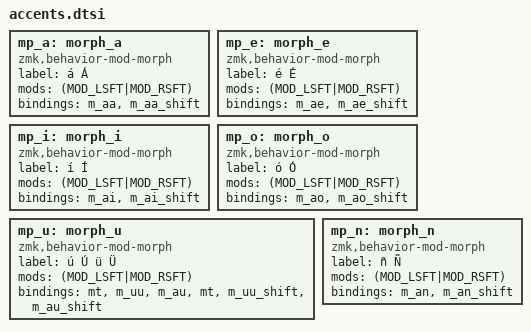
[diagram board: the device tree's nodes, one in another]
mp_a: morph_a {
    compatible = "zmk,behavior-mod-morph";
    label = "á Á";
    #binding-cells = <0>;
    mods = <(MOD_LSFT|MOD_RSFT)>;
    bindings = <&m_aa>, <&m_aa_shift>;
};

mp_e: morph_e {
    compatible = "zmk,behavior-mod-morph";
    label = "é É";
    #binding-cells = <0>;
    mods = <(MOD_LSFT|MOD_RSFT)>;
    bindings = <&m_ae>, <&m_ae_shift>;
};

mp_i: morph_i {
    compatible = "zmk,behavior-mod-morph";
    label = "í Í";
    #binding-cells = <0>;
    mods = <(MOD_LSFT|MOD_RSFT)>;
    bindings = <&m_ai>, <&m_ai_shift>;
};

mp_o: morph_o {
    compatible = "zmk,behavior-mod-morph";
    label = "ó Ó";
    #binding-cells = <0>;
    mods = <(MOD_LSFT|MOD_RSFT)>;
    bindings = <&m_ao>, <&m_ao_shift>;
};

mp_u: morph_u {
    compatible = "zmk,behavior-mod-morph";
    label = "ú Ú ü Ü";
    #binding-cells = <0>;
    mods = <(MOD_LSFT|MOD_RSFT)>;
    bindings = <&mt &m_uu &m_au>, <&mt &m_uu_shift &m_au_shift>;
};

mp_n: morph_n {
    compatible = "zmk,behavior-mod-morph";
    label = "ñ Ñ";
    #binding-cells = <0>;
    mods = <(MOD_LSFT|MOD_RSFT)>;
    bindings = <&m_an>, <&m_an_shift>;
};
